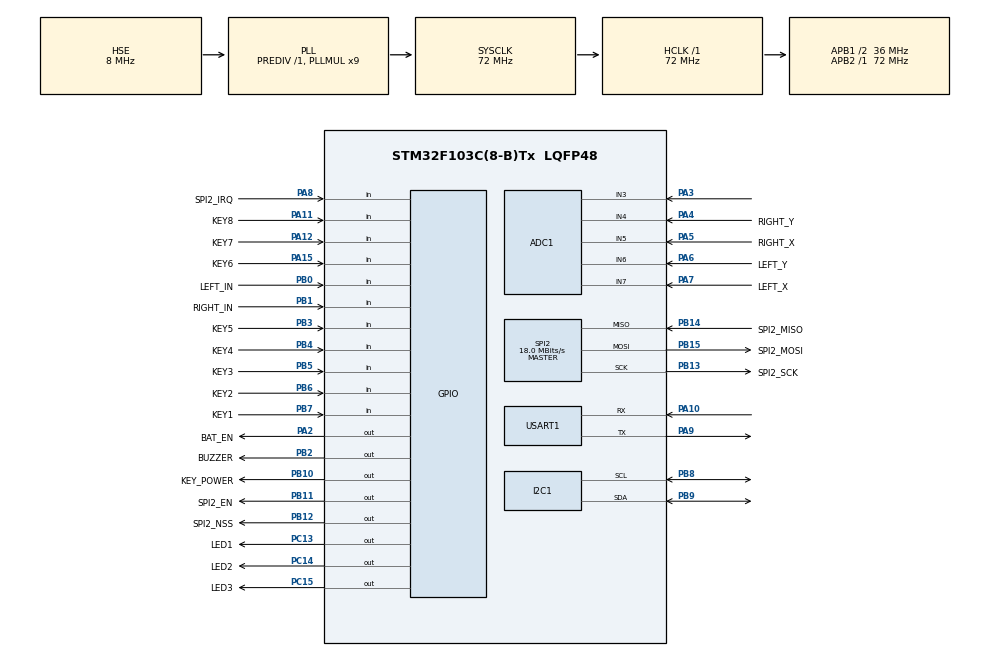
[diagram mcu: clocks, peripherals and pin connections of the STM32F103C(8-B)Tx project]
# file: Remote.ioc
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ADC1.Channel-0\#ChannelRegularConversion=ADC_CHANNEL_4
ADC1.Channel-1\#ChannelRegularConversion=ADC_CHANNEL_5
ADC1.Channel-2\#ChannelRegularConversion=ADC_CHANNEL_6
ADC1.Channel-3\#ChannelRegularConversion=ADC_CHANNEL_7
ADC1.Channel-4\#ChannelRegularConversion=ADC_CHANNEL_7
ADC1.ContinuousConvMode=ENABLE
ADC1.EnableAnalogWatchDog=false
ADC1.EnableInjectedConversion=DISABLE
ADC1.NbrOfConversion=5
ADC1.NbrOfConversionFlag=1
ADC1.Rank-0\#ChannelRegularConversion=1
ADC1.Rank-1\#ChannelRegularConversion=2
ADC1.Rank-2\#ChannelRegularConversion=3
ADC1.Rank-3\#ChannelRegularConversion=4
ADC1.Rank-4\#ChannelRegularConversion=5
ADC1.SamplingTime-0\#ChannelRegularConversion=ADC_SAMPLETIME_13CYCLES_5
ADC1.SamplingTime-1\#ChannelRegularConversion=ADC_SAMPLETIME_13CYCLES_5
ADC1.SamplingTime-2\#ChannelRegularConversion=ADC_SAMPLETIME_13CYCLES_5
ADC1.SamplingTime-3\#ChannelRegularConversion=ADC_SAMPLETIME_13CYCLES_5
ADC1.SamplingTime-4\#ChannelRegularConversion=ADC_SAMPLETIME_1CYCLE_5
ADC1.master=1
Dma.ADC1.0.Direction=DMA_PERIPH_TO_MEMORY
Dma.ADC1.0.Instance=DMA1_Channel1
Dma.ADC1.0.MemDataAlignment=DMA_MDATAALIGN_HALFWORD
Dma.ADC1.0.MemInc=DMA_MINC_ENABLE
Dma.ADC1.0.Mode=DMA_CIRCULAR
Dma.ADC1.0.PeriphDataAlignment=DMA_PDATAALIGN_HALFWORD
Dma.ADC1.0.PeriphInc=DMA_PINC_DISABLE
Dma.ADC1.0.Priority=DMA_PRIORITY_LOW
Dma.Request0=ADC1
I2C1.I2C_Mode=I2C_Fast
Mcu.Family=STM32F1
Mcu.Name=STM32F103C(8-B)Tx
Mcu.Package=LQFP48
NVIC.DMA1_Channel1_IRQn=true\:0\:0\:false\:false\:true\:false\:true\:true
NVIC.PriorityGroup=NVIC_PRIORITYGROUP_4
PA10.Mode=Asynchronous
PA10.Signal=USART1_RX
PA11.GPIO_Label=KEY8
PA11.GPIO_PuPd=GPIO_PULLUP
PA11.Signal=GPIO_Input
PA12.GPIO_Label=KEY7
PA12.GPIO_PuPd=GPIO_PULLUP
PA12.Signal=GPIO_Input
PA13.Mode=Serial_Wire
PA13.Signal=SYS_JTMS-SWDIO
PA14.Mode=Serial_Wire
PA14.Signal=SYS_JTCK-SWCLK
PA15.GPIO_Label=KEY6
PA15.GPIO_PuPd=GPIO_PULLUP
PA15.Signal=GPIO_Input
PA2.GPIO_Label=BAT_EN
PA2.PinState=GPIO_PIN_SET
PA2.Signal=GPIO_Output
PA3.Signal=ADCx_IN3
PA4.GPIO_Label=RIGHT_Y
PA4.Signal=ADCx_IN4
PA5.GPIO_Label=RIGHT_X
PA5.Signal=ADCx_IN5
PA6.GPIO_Label=LEFT_Y
PA6.Signal=ADCx_IN6
PA7.GPIO_Label=LEFT_X
PA7.Signal=ADCx_IN7
PA8.GPIO_Label=SPI2_IRQ
PA8.Signal=GPIO_Input
PA9.Mode=Asynchronous
PA9.Signal=USART1_TX
PB0.GPIO_Label=LEFT_IN
PB0.GPIO_PuPd=GPIO_PULLUP
PB0.Signal=GPIO_Input
PB1.GPIO_Label=RIGHT_IN
PB1.GPIO_PuPd=GPIO_PULLUP
PB1.Signal=GPIO_Input
PB10.GPIO_Label=KEY_POWER
PB10.PinState=GPIO_PIN_SET
PB10.Signal=GPIO_Output
PB11.GPIO_Label=SPI2_EN
PB11.GPIO_Speed=GPIO_SPEED_FREQ_HIGH
PB11.Signal=GPIO_Output
PB12.GPIO_Label=SPI2_NSS
PB12.GPIO_Speed=GPIO_SPEED_FREQ_HIGH
PB12.PinState=GPIO_PIN_SET
PB12.Signal=GPIO_Output
PB13.GPIO_Label=SPI2_SCK
PB13.Mode=Full_Duplex_Master
PB13.Signal=SPI2_SCK
PB14.GPIO_Label=SPI2_MISO
PB14.Mode=Full_Duplex_Master
PB14.Signal=SPI2_MISO
PB15.GPIO_Label=SPI2_MOSI
PB15.Mode=Full_Duplex_Master
PB15.Signal=SPI2_MOSI
PB2.GPIO_Label=BUZZER
PB2.PinState=GPIO_PIN_SET
PB2.Signal=GPIO_Output
PB3.GPIO_Label=KEY5
PB3.GPIO_PuPd=GPIO_PULLUP
PB3.Signal=GPIO_Input
PB4.GPIO_Label=KEY4
PB4.GPIO_PuPd=GPIO_PULLUP
PB4.Signal=GPIO_Input
PB5.GPIO_Label=KEY3
PB5.GPIO_PuPd=GPIO_PULLUP
PB5.Signal=GPIO_Input
PB6.GPIO_Label=KEY2
PB6.GPIO_PuPd=GPIO_PULLUP
PB6.Signal=GPIO_Input
PB7.GPIO_Label=KEY1
PB7.GPIO_PuPd=GPIO_PULLUP
PB7.Signal=GPIO_Input
PB8.Mode=I2C
PB8.Signal=I2C1_SCL
PB9.Mode=I2C
PB9.Signal=I2C1_SDA
PC13-TAMPER-RTC.GPIO_Label=LED1
PC13-TAMPER-RTC.PinState=GPIO_PIN_SET
PC13-TAMPER-RTC.Signal=GPIO_Output
PC14-OSC32_IN.GPIO_Label=LED2
PC14-OSC32_IN.PinState=GPIO_PIN_SET
PC14-OSC32_IN.Signal=GPIO_Output
PC15-OSC32_OUT.GPIO_Label=LED3
PC15-OSC32_OUT.PinState=GPIO_PIN_SET
PC15-OSC32_OUT.Signal=GPIO_Output
PD0-OSC_IN.Mode=HSE-External-Oscillator
PD0-OSC_IN.Signal=RCC_OSC_IN
PD1-OSC_OUT.Mode=HSE-External-Oscillator
PD1-OSC_OUT.Signal=RCC_OSC_OUT
ProjectManager.HeapSize=0x200
ProjectManager.StackSize=0x400
ProjectManager.TargetToolchain=MDK-ARM V5.32
RCC.ADCPresc=RCC_ADCPCLK2_DIV6
RCC.AHBFreq_Value=72000000
RCC.APB1CLKDivider=RCC_HCLK_DIV2
RCC.APB1Freq_Value=36000000
RCC.APB1TimFreq_Value=72000000
RCC.APB2Freq_Value=72000000
RCC.APB2TimFreq_Value=72000000
RCC.HCLKFreq_Value=72000000
RCC.PLLMUL=RCC_PLL_MUL9
RCC.PLLSourceVirtual=RCC_PLLSOURCE_HSE
RCC.SYSCLKFreq_VALUE=72000000
RCC.SYSCLKSource=RCC_SYSCLKSOURCE_PLLCLK
RCC.USBFreq_Value=72000000
SH.ADCx_IN3.0=ADC1_IN3,IN3
SH.ADCx_IN4.0=ADC1_IN4,IN4
SH.ADCx_IN5.0=ADC1_IN5,IN5
SH.ADCx_IN6.0=ADC1_IN6,IN6
SH.ADCx_IN7.0=ADC1_IN7,IN7
SPI2.CalculateBaudRate=18.0 MBits/s
SPI2.Direction=SPI_DIRECTION_2LINES
SPI2.Mode=SPI_MODE_MASTER
SPI2.VirtualType=VM_MASTER
USART1.VirtualMode=VM_ASYNC
board=custom

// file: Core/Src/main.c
/* USER CODE BEGIN Header */
/**
  ******************************************************************************
  * @file           : main.c
  * @brief          : Main program body
  ******************************************************************************
  * @attention
  *
  * Copyright (c) 2026 STMicroelectronics.
  * All rights reserved.
  *
  * This software is licensed under terms that can be found in the LICENSE file
  * in the root directory of this software component.
  * If no LICENSE file comes with this software, it is provided AS-IS.
  *
  ******************************************************************************
  */
/* USER CODE END Header */
#include "main.h"
#include "adc.h"
#include "dma.h"
#include "i2c.h"
#include "spi.h"
#include "usart.h"
#include "gpio.h"

/* USER CODE BEGIN Includes */
#include "APP_FreeRTOS_Task.h"
/* USER CODE END Includes */

void SystemClock_Config(void);

int main(void)
{

  /* MCU Configuration--------------------------------------------------------*/

  /* Reset of all peripherals, Initializes the Flash interface and the Systick. */
  HAL_Init();

  /* Configure the system clock */
  SystemClock_Config();

  /* Initialize all configured peripherals */
  MX_GPIO_Init();
  MX_DMA_Init();
  MX_USART1_UART_Init();
  MX_SPI2_Init();
  MX_ADC1_Init();
  MX_I2C1_Init();
  /* USER CODE BEGIN 2 */

  // 实现最初的日志输出打印
  // HAL_UART_Transmit(&huart1, (uint8_t*)"Hello, World!\r\n", 15, HAL_MAX_DELAY);

  // 使用C语言标准的日志输出功能printf
  debug_printf("Hello, Remote!\r\n");

  // 还没有启动RTOS => 此时的延时只能使用HAL_DELAY
  Int_SI24R1_Init();  //SI24R1初始化测试

  // 启动FreeRTOS => 后续的代码都不再执行
  APP_FreeRTOS_start();

  /* USER CODE END 2 */

  /* Infinite loop */
  while (1)
  {

  }
}

void SystemClock_Config(void)
{
  RCC_OscInitTypeDef RCC_OscInitStruct = {0};
  RCC_ClkInitTypeDef RCC_ClkInitStruct = {0};
  RCC_PeriphCLKInitTypeDef PeriphClkInit = {0};

  /** Initializes the RCC Oscillators according to the specified parameters
  * in the RCC_OscInitTypeDef structure.
  */
  RCC_OscInitStruct.OscillatorType = RCC_OSCILLATORTYPE_HSE;
  RCC_OscInitStruct.HSEState = RCC_HSE_ON;
  RCC_OscInitStruct.HSEPredivValue = RCC_HSE_PREDIV_DIV1;
  RCC_OscInitStruct.HSIState = RCC_HSI_ON;
  RCC_OscInitStruct.PLL.PLLState = RCC_PLL_ON;
  RCC_OscInitStruct.PLL.PLLSource = RCC_PLLSOURCE_HSE;
  RCC_OscInitStruct.PLL.PLLMUL = RCC_PLL_MUL9;
  if (HAL_RCC_OscConfig(&RCC_OscInitStruct) != HAL_OK)
  {
    Error_Handler();
  }

  /** Initializes the CPU, AHB and APB buses clocks
  */
  RCC_ClkInitStruct.ClockType = RCC_CLOCKTYPE_HCLK|RCC_CLOCKTYPE_SYSCLK
                              |RCC_CLOCKTYPE_PCLK1|RCC_CLOCKTYPE_PCLK2;
  RCC_ClkInitStruct.SYSCLKSource = RCC_SYSCLKSOURCE_PLLCLK;
  RCC_ClkInitStruct.AHBCLKDivider = RCC_SYSCLK_DIV1;
  RCC_ClkInitStruct.APB1CLKDivider = RCC_HCLK_DIV2;
  RCC_ClkInitStruct.APB2CLKDivider = RCC_HCLK_DIV1;

  if (HAL_RCC_ClockConfig(&RCC_ClkInitStruct, FLASH_LATENCY_2) != HAL_OK)
  {
    Error_Handler();
  }
  PeriphClkInit.PeriphClockSelection = RCC_PERIPHCLK_ADC;
  PeriphClkInit.AdcClockSelection = RCC_ADCPCLK2_DIV6;
  if (HAL_RCCEx_PeriphCLKConfig(&PeriphClkInit) != HAL_OK)
  {
    Error_Handler();
  }
}

void Error_Handler(void)
{
  __disable_irq();
  while (1)
  {
  }
}
